# NM1500_v1 register map
File version: 1.0
Registers are 32-bit, read-write, reset 0x0 unless marked. A register's access mark holds for its fields unless they carry their own. Offsets are from the block's base; [hi:lo] are bit positions; {n}, {i} and the like mark numbered series.

## GP0 — GPIO Register Map
Base 0x50004000
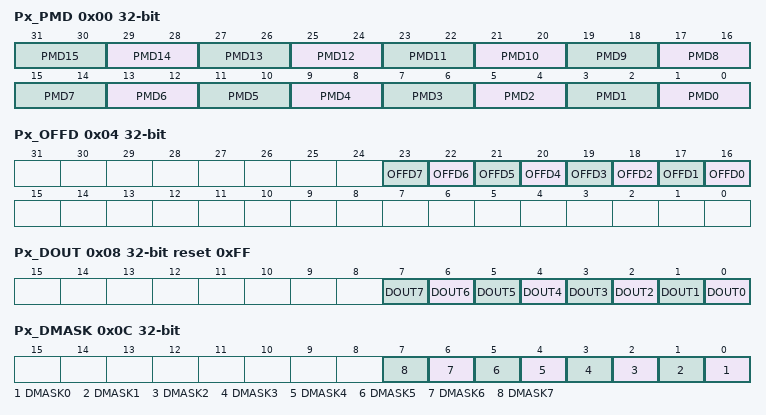
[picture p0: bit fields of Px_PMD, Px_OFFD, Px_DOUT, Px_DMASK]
0x00 Px_PMD — GPIO Port Bit Mode Control
  [all] fields
    0=GPIO port [n] pin is in Input mode; 1=GPIO port [n] pin is in Push-pull Output mode; 2=GPIO port [n] pin is in Open-drain Output mode; 3=GPIO port [n] pin is in Quasi-bidirectional mode
  [2n+1:2n] PMD{n} (n=0..15) — Port x bit m Mode Control. Determine each I/O mode of Px pins.
0x04 Px_OFFD — GPIO Port Bit Off Digital Enable
  [all] fields
    0=I/O digital input path Enabled; 1=I/O digital input path Disabled (digital input tied to low)
  [n+16] OFFD{n} (n=0..7) — Port x bit m off digital input path. Each of these bits is used to turn off the digital input path of port n bit m pin. If input is analog signal, users can turn off digital input path to avoid input current leakage.
0x08 Px_DOUT reset 0xFF — GPIO Port Data Output
  [all] fields
    0=GPIO port [0/1/2/3/4/5/6/7/8/9/A] Pin[m] will drive Low if the GPIO pin is configured as Push-pull output, Open-drain output or Quasi-bidirectional mode; 1=GPIO port [0/1/2/3/4/5/6/7/8/9/A] Pin[m] will drive High if the GPIO pin is configured as Push-pull output or Quasi-bidirectional mode
  [n] DOUT{n} (n=0..7) — Port x bit m output. Each of these bits control the status of port n bit m when this pin is configures as output, open-drain, or quasi bi-directional mode.
0x0C Px_DMASK — GPIO Port Data Output Write Mask
  [all] fields
    0=Corresponding Pn_DOUT[m] bit can be updated; 1=Corresponding Pn_DOUT[m] bit protected
  [n] DMASK{n} (n=0..7) — Port x bit m data output write mask. These bits are used to protect the corresponding register of Pn_DOUT[m]. When set the DMASK[m] to 1, the writing to Pn_DOUT[m] bit is ignored. The write to port pin latch is masked.
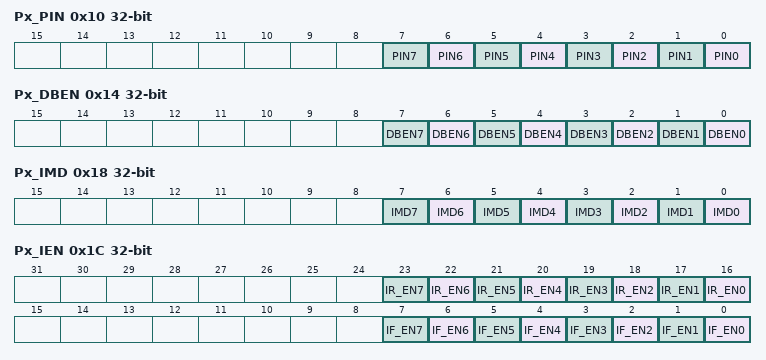
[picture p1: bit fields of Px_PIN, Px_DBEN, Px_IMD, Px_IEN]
0x10 Px_PIN ro (reset mask 0xFFFFFF00) — GPIO Port Pin Value
  [n] PIN{n} (n=0..7) — Port x Bit m Pin Value. Each bit of the register reflects the actual status of the respective port pin. If bit is 1, it indicates the corresponding pin status is high, else the pin status is low
0x14 Px_DBEN — GPIO Port De-bounce Enable
  [all] fields
    0=Bit[m] de-bounce function Disabled; 1=Bit[m] de-bounce function Enabled
  [n] DBEN{n} (n=0..7) — Port x Bit m Input De-bounce Enable. DBEN[m] is used to enable the de-bounce function for each corresponding bit. DBEN[m] is valid for 'edge-triggered' interrupt only and is ignored for 'level triggered' interrupt. If the input signal pulse width can't be sampled by continuous two de-bounce sample cycle The input signal transition is seen as the signal bounce and will not trigger the interrupt. The de-bounce clock is controlled by DBNCECON register.
0x18 Px_IMD — GPIO Port Interrupt Mode Select
  [all] fields
    0=Edge triggered interrupt; 1=Level triggered interrupt
  [n] IMD{n} (n=0..7) — Port x bit m Edge or Level Triggered Interrupt Control. IMD[m] decides the pin interrupt triggered by level or edge. If the interrupt is by edge trigger, the trigger source can be controlled by de-bounce. If the interrupt is by level trigger, the input source is sampled by one HCLK clock and generates the interrupt.
0x1C Px_IEN — GPIO Port Interrupt Enable
  [n+16] IR_EN{n} (n=0..7) — Port x Bit m Interrupt Enabled for Rising Edge or High Level Input. IR_EN[m] enables the interrupt for each of the corresponding input of Port x. Set bit to 1 also enable the pin wakeup function.
    0=Port n bit m high-level or rising edge interrupt Disabled; 1=Port n bit m high-level or rising edge interrupt Enabled
  [n] IF_EN{n} (n=0..7) — Port x Bit m Interrupt Enabled for Falling Edge or Low Level Input. IF_EN[n] enables the interrupt for each of the corresponding input of Port x. Set bit to 1 also enable the pin wakeup function.
    0=Port n bit m low-level or falling edge interrupt Disabled; 1=Port n bit m low-level or falling edge interrupt Enabled
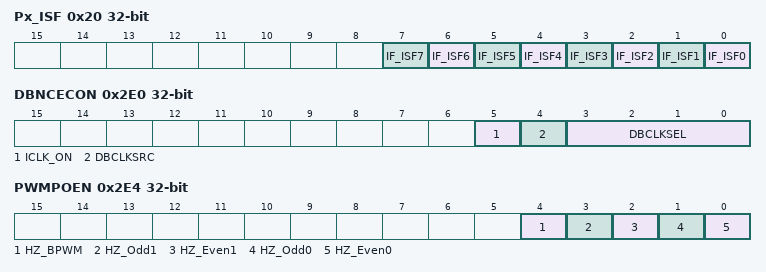
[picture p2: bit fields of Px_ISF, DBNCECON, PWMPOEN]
0x20 Px_ISF reset not defined — GPIO Port Interrupt Source Flag
  [all] fields
    0=No interrupt at Port x. No effect; 1=Indicates Port x bit m detects a trigger event. Clear the corresponding pending interrupt
  [n] IF_ISF{n} (n=0..7) — Port x Bit m Trigger Source Indicator. These bits are edge/level trigger event indicators of each pin of Port x, if GPG0_INT or GPG1_INT enable bit is set, the corresponding interrupt service routine will be served. Note that P3.2 and P3.3 will only vector to INT0_INT and INT1_INT ISRs if its own interrupt is enabled. Read :
0x2E0 DBNCECON — External Interrupt De-bounce Control
  [5] ICLK_ON — Interrupt Clock On Mode. It is recommended to turn off this bit to save system power if no special application concern.
    0=Edge detection circuit is active only if I/O pin corresponding Pn_IEN bit is set to 1; 1=All I/O pins edge detection circuit is always active after reset
  [4] DBCLKSRC — De-bounce Counter Clock Source Selection
    0=De-bounce counter clock source is the HCLK; 1=De-bounce counter clock source is the internal 10 kHz low speed oscillator
  [3:0] DBCLKSEL — De-bounce sampling cycle selection.
0x2E4 PWMPOEN (reset mask 0xFFFFFF00) — PWM Port Output Enable
  [4] HZ_BPWM — Basic PWM Ports Output Control. The initial value is loaded from config0[CHZ_BPWM] after any reset.
    0=The driving mode of Basic PWM ports are controlled by GPIO mode register (Pn_PMD) or multi-function register (Pn_MFP); 1=The driving mode of Basic PWM ports are forced in tri-state (Hi-Z) all the time
  [3] HZ_Odd1 — PWM Unit1 Odd Ports Output Control. The initial value is loaded from config0[CHZ_Odd1] after any reset.
    0=The driving mode of PWM unit1 odd ports are controlled by GPIO mode register (Pn_PMD) or multi-function register (Pn_MFP); 1=The driving mode of PWM unit1 odd ports are forced in tri-state (Hi-Z) all the time
  [2] HZ_Even1 — PWM Unit1 Even Ports Output Control. The initial value is loaded from config0[CHZ_Even1] after any reset.
    0=The driving mode of PWM unit1 even ports are controlled by GPIO mode register (Pn_PMD) or multi-function register (Pn_MFP); 1=The driving mode of PWM unit1 even ports are forced in tri-state (Hi-Z) all the time
  [1] HZ_Odd0 — PWM Unit0 Odd Ports Output Control. The initial value is loaded from config0[CHZ_Odd0] after any reset.
    0=The driving mode of PWM unit0 odd ports are controlled by GPIO mode register (Pn_PMD) or multi-function register (Pn_MFP); 1=The driving mode of PWM unit0 odd ports are forced in tri-state (Hi-Z) all the time
  [0] HZ_Even0 — PWM Unit0 Even Ports Output Control. The initial value is loaded from config0[CHZ_Even0] after any reset.
    0=The driving mode of PWM unit0 even ports are controlled by GPIO mode register (Pn_PMD) or multi-function register (Pn_MFP); 1=The driving mode of PWM unit0 even ports are forced in tri-state (Hi-Z) all the time

## GP10 — GPIO Register Map
Base 0x50004280
Registers as GP0, without DBNCECON, PWMPOEN.

## GP1 — GPIO Register Map
Base 0x50004040
Registers as GP0, without DBNCECON, PWMPOEN.

## GP2 — GPIO Register Map
Base 0x50004080
Registers as GP0, without DBNCECON, PWMPOEN.

## GP3 — GPIO Register Map
Base 0x500040C0
Registers as GP0, without DBNCECON, PWMPOEN.

## GP4 — GPIO Register Map
Base 0x50004100
Registers as GP0, without DBNCECON, PWMPOEN.

## GP5 — GPIO Register Map
Base 0x50004140
Registers as GP0, without DBNCECON, PWMPOEN.

## GP6 — GPIO Register Map
Base 0x50004180
Registers as GP0, without DBNCECON, PWMPOEN.

## GP7 — GPIO Register Map
Base 0x500041C0
Registers as GP0, without DBNCECON, PWMPOEN.

## GP8 — GPIO Register Map
Base 0x50004200
Registers as GP0, without DBNCECON, PWMPOEN.

## GP9 — GPIO Register Map
Base 0x50004240
Registers as GP0, without DBNCECON, PWMPOEN.
